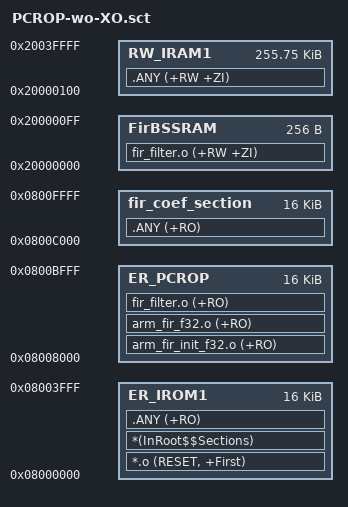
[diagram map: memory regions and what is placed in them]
; *************************************************************
; *** Scatter-Loading Description File generated by uVision ***
; *************************************************************

LR_IROM1 0x08000000 0x00004000  {    ; load region size_region
  ER_IROM1 0x08000000 0x00004000  {  ; load address = execution address
   *.o (RESET, +First)
   *(InRoot$$Sections)
   .ANY (+RO)
  }
    FirBSSRAM  0x20000000 0x100 ; RW and Zero Initialized data for fir filter  
  { 
	fir_filter.o (+RW +ZI)
  }  
  RW_IRAM1 0x20000100 0x0003FF00  {  ; RW data
   .ANY (+RW +ZI)
  }
}

; *********************
; *** PCROP-ed area ***
; *********************

LR_PCROP 0x08008000 0x00004000  {
  ER_PCROP 0x08008000 0x00004000  {  ; load address = execution address
	arm_fir_init_f32.o (+RO)
	arm_fir_f32.o (+RO)
	fir_filter.o (+RO)	
  }
}

; **************************************************
; ***  Write protected area for FIR coefficients ***
; **** *********************************************
LR_DATA 0x0800C000 0x00004000  {
  fir_coef_section 0x0800C000 0x00004000  {  
	.ANY (+RO)		
  }
}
